AUTOSAR XML (schema 4-2-2)
package /ARPackage_1
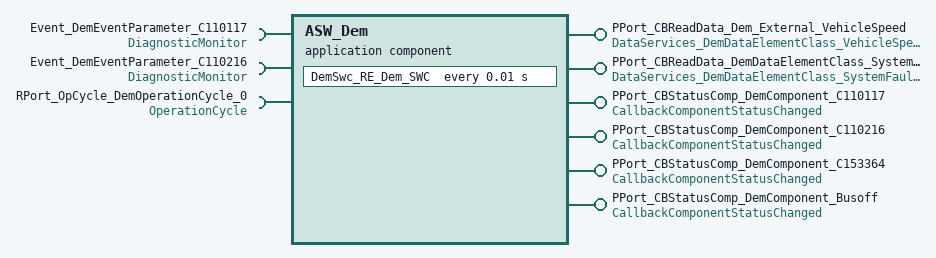
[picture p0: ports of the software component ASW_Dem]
  application sw component type ASW_Dem
    6 x provide port:
      PPort_CBReadData_Dem_External_VehicleSpeed: provided-interface=DataServices_DemDataElementClass_VehicleSpeed
      PPort_CBReadData_DemDataElementClass_SystemFaultRank: provided-interface=DataServices_DemDataElementClass_SystemFaultRank
      PPort_CBStatusComp_DemComponent_C110117: provided-interface=CallbackComponentStatusChanged
      PPort_CBStatusComp_DemComponent_C110216: provided-interface=CallbackComponentStatusChanged
      PPort_CBStatusComp_DemComponent_C153364: provided-interface=CallbackComponentStatusChanged
      PPort_CBStatusComp_DemComponent_Busoff: provided-interface=CallbackComponentStatusChanged
    require port Event_DemEventParameter_C110117: required-interface=DiagnosticMonitor
    require port Event_DemEventParameter_C110216: required-interface=DiagnosticMonitor
    require port RPort_OpCycle_DemOperationCycle_0: required-interface=OperationCycle
    behavior IB_Dem_SWC
      timing event TimingEvent_Dem_SWC: start-on-event=DemSwc_RE_Dem_SWC, period=0.01
      operation invoked event OIE_CSDataElementClass_VehicleSpeed_ReadData: start-on-event=DemSwc_RE_CSDataElementClass_VehicleSpeed_ReadData, operation=PPort_CBReadData_Dem_External_VehicleSpeed.ReadData
      operation invoked event OIE_CSDataElementClass_SystemFaultRank_ReadData: start-on-event=DemSwc_RE_CSDataElementClass_SystemFaultRank_ReadData, operation=PPort_CBReadData_DemDataElementClass_SystemFaultRank.ReadData
      operation invoked event OperationInvokedEvent_0: start-on-event=RunnableEntity_0, operation=PPort_CBStatusComp_DemComponent_C110117.ComponentStatusChanged
      4 x runnable:
        DemSwc_RE_Dem_SWC: symbol=DemSwc_RE_Dem_SWC_func
          12 x sync call:
            SynchronousServerCallPoint_0: operation=Event_DemEventParameter_C110117.SetEventStatus
            SynchronousServerCallPoint_1: operation=Event_DemEventParameter_C110117.ResetEventStatus
            SynchronousServerCallPoint_2: operation=Event_DemEventParameter_C110117.PrestoreFreezeFrame
            SynchronousServerCallPoint_3: operation=Event_DemEventParameter_C110117.ClearPrestoredFreezeFrame
            SynchronousServerCallPoint_4: operation=Event_DemEventParameter_C110117.ResetEventDebounceStatus
            SynchronousServerCallPoint_5: operation=Event_DemEventParameter_C110216.SetEventStatus
            SynchronousServerCallPoint_6: operation=Event_DemEventParameter_C110216.ResetEventStatus
            SynchronousServerCallPoint_7: operation=Event_DemEventParameter_C110216.PrestoreFreezeFrame
            SynchronousServerCallPoint_8: operation=Event_DemEventParameter_C110216.ClearPrestoredFreezeFrame
            SynchronousServerCallPoint_9: operation=Event_DemEventParameter_C110216.ResetEventDebounceStatus
            SynchronousServerCallPoint_10: operation=RPort_OpCycle_DemOperationCycle_0.SetOperationCycleState
            SynchronousServerCallPoint_11: operation=RPort_OpCycle_DemOperationCycle_0.GetOperationCycleState
        DemSwc_RE_CSDataElementClass_VehicleSpeed_ReadData: symbol=DemSwc_RE_CSDataElementClass_VehicleSpeed_ReadData_func
        DemSwc_RE_CSDataElementClass_SystemFaultRank_ReadData: symbol=DemSwc_RE_CSDataElementClass_SystemFaultRank_ReadData_func
        RunnableEntity_0: symbol=RunnableEntity_0_func
